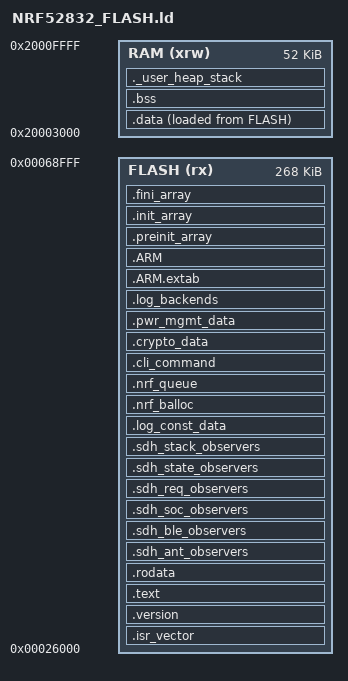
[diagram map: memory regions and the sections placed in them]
/* Entry Point */
ENTRY(Reset_Handler)

/* Highest address of the user mode stack */
_estack = ORIGIN(RAM) + LENGTH(RAM);	/* end of "RAM" Ram type memory */

_Min_Heap_Size = 0x200;	/* required amount of heap  */
_Min_Stack_Size = 0x400;	/* required amount of stack */

/* Memories definition */
MEMORY
{
  FLASH  (rx)     : ORIGIN = 0x00026000,   LENGTH = 268K
  RAM    (xrw)    : ORIGIN = 0x20003000,   LENGTH = 64K - 12K
}

/* Sections */
SECTIONS
{
  
  /* The startup code into "FLASH" Rom type memory */
  .isr_vector :
  {
    . = ALIGN(4);
    __isr_vector_addr = .;
    KEEP(*(.isr_vector)) /* Startup code */
    . = ALIGN(4);
  } >FLASH

  .version :
  {
    . = ALIGN(1024);
    KEEP(*(.version)) 
    . = ALIGN(4);
  } >FLASH

  /* The program code and other data into "FLASH" Rom type memory */
  .text :
  {
    . = ALIGN(4);
    *(.text)           /* .text sections (code) */
    *(.text*)          /* .text* sections (code) */
    *(.glue_7)         /* glue arm to thumb code */
    *(.glue_7t)        /* glue thumb to arm code */
    *(.eh_frame)

    KEEP (*(.init))
    KEEP (*(.fini))

    . = ALIGN(4);
    _etext = .;        /* define a global symbols at end of code */
  } >FLASH

  /* Constant data into "FLASH" Rom type memory */
  .rodata :
  {
    . = ALIGN(4);
    *(.rodata)         /* .rodata sections (constants, strings, etc.) */
    *(.rodata*)        /* .rodata* sections (constants, strings, etc.) */
    . = ALIGN(4);
  } >FLASH

  .sdh_ant_observers :
  {
    PROVIDE(__start_sdh_ant_observers = .);
    KEEP(*(SORT(.sdh_ant_observers*)))
    PROVIDE(__stop_sdh_ant_observers = .);
  } > FLASH
  .sdh_ble_observers :
  {
    PROVIDE(__start_sdh_ble_observers = .);
    KEEP(*(SORT(.sdh_ble_observers*)))
    PROVIDE(__stop_sdh_ble_observers = .);
  } > FLASH
  .sdh_soc_observers :
  {
    PROVIDE(__start_sdh_soc_observers = .);
    KEEP(*(SORT(.sdh_soc_observers*)))
    PROVIDE(__stop_sdh_soc_observers = .);
  } > FLASH
  .sdh_req_observers :
  {
    PROVIDE(__start_sdh_req_observers = .);
    KEEP(*(SORT(.sdh_req_observers*)))
    PROVIDE(__stop_sdh_req_observers = .);
  } > FLASH
  .sdh_state_observers :
  {
    PROVIDE(__start_sdh_state_observers = .);
    KEEP(*(SORT(.sdh_state_observers*)))
    PROVIDE(__stop_sdh_state_observers = .);
  } > FLASH
  .sdh_stack_observers :
  {
    PROVIDE(__start_sdh_stack_observers = .);
    KEEP(*(SORT(.sdh_stack_observers*)))
    PROVIDE(__stop_sdh_stack_observers = .);
  } > FLASH
  .log_const_data :
  {
    PROVIDE(__start_log_const_data = .);
    KEEP(*(SORT(.log_const_data*)))
    PROVIDE(__stop_log_const_data = .);
  } > FLASH
    .nrf_balloc :
  {
    PROVIDE(__start_nrf_balloc = .);
    KEEP(*(.nrf_balloc))
    PROVIDE(__stop_nrf_balloc = .);
  } > FLASH
    .nrf_queue :
  {
    PROVIDE(__start_nrf_queue = .);
    KEEP(*(.nrf_queue))
    PROVIDE(__stop_nrf_queue = .);
  } > FLASH
    .cli_command :
  {
    PROVIDE(__start_cli_command = .);
    KEEP(*(.cli_command))
    PROVIDE(__stop_cli_command = .);
  } > FLASH
  .crypto_data :
  {
    PROVIDE(__start_crypto_data = .);
    KEEP(*(SORT(.crypto_data*)))
    PROVIDE(__stop_crypto_data = .);
  } > FLASH
  .pwr_mgmt_data :
  {
    PROVIDE(__start_pwr_mgmt_data = .);
    KEEP(*(SORT(.pwr_mgmt_data*)))
    PROVIDE(__stop_pwr_mgmt_data = .);
  } > FLASH
  .log_backends :
  {
    PROVIDE(__start_log_backends = .);
    KEEP(*(SORT(.log_backends*)))
    PROVIDE(__stop_log_backends = .);
  } > FLASH


  .ARM.extab   : { 
    . = ALIGN(4);
    *(.ARM.extab* .gnu.linkonce.armextab.*)
    . = ALIGN(4);
  } >FLASH
  
  .ARM : {
    . = ALIGN(4);
    __exidx_start = .;
    *(.ARM.exidx*)
    __exidx_end = .;
    . = ALIGN(4);
  } >FLASH

  .preinit_array     :
  {
    . = ALIGN(4);
    PROVIDE_HIDDEN (__preinit_array_start = .);
    KEEP (*(.preinit_array*))
    PROVIDE_HIDDEN (__preinit_array_end = .);
    . = ALIGN(4);
  } >FLASH
  
  .init_array :
  {
    . = ALIGN(4);
    PROVIDE_HIDDEN (__init_array_start = .);
    KEEP (*(SORT(.init_array.*)))
    KEEP (*(.init_array*))
    PROVIDE_HIDDEN (__init_array_end = .);
    . = ALIGN(4);
  } >FLASH
  
  .fini_array :
  {
    . = ALIGN(4);
    PROVIDE_HIDDEN (__fini_array_start = .);
    KEEP (*(SORT(.fini_array.*)))
    KEEP (*(.fini_array*))
    PROVIDE_HIDDEN (__fini_array_end = .);
    . = ALIGN(4);
  } >FLASH

  /* Used by the startup to initialize data */
  _sidata = LOADADDR(.data);

  /* Initialized data sections into "RAM" Ram type memory */
  .data : 
  {
    __data_start__ = .;
  
    . = ALIGN(4);
    _sdata = .;        /* create a global symbol at data start */
    *(.data)           /* .data sections */
    *(.data*)          /* .data* sections */

    . = ALIGN(4);
    _edata = .;        /* define a global symbol at data end */
    
  } >RAM AT> FLASH

  /* Uninitialized data section into "RAM" Ram type memory */
  . = ALIGN(4);
  .bss :
  {
    /* This is used by the startup in order to initialize the .bss section */
    _sbss = .;         /* define a global symbol at bss start */
    __bss_start__ = _sbss;
    *(.bss)
    *(.bss*)
    *(COMMON)

    . = ALIGN(4);
    _ebss = .;         /* define a global symbol at bss end */
    __bss_end__ = _ebss;
  } >RAM

  /* User_heap_stack section, used to check that there is enough "RAM" Ram  type memory left */
  ._user_heap_stack :
  {
    . = ALIGN(8);
    PROVIDE ( end = . );
    PROVIDE ( _end = . );
    . = . + _Min_Heap_Size;
    . = . + _Min_Stack_Size;
    . = ALIGN(8);
  } >RAM

  /* Remove information from the compiler libraries */
  /DISCARD/ :
  {
    libc.a ( * )
    libm.a ( * )
    libgcc.a ( * )
  }

  .ARM.attributes 0 : { *(.ARM.attributes) }
}
